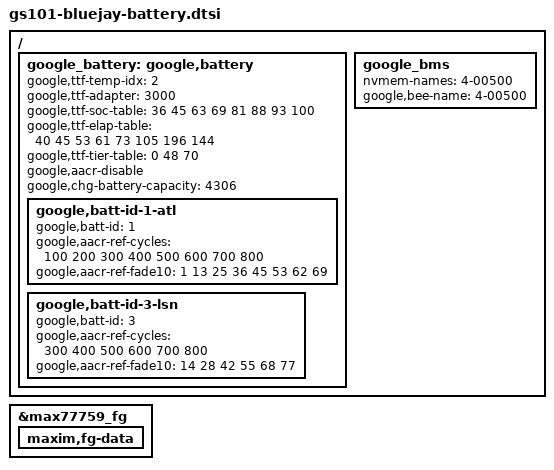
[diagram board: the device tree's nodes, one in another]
// SPDX-License-Identifier: GPL-2.0-only
/*
 * Battery device tree entries specific to bluejay
 *
 * Copyright 2021 Google,LLC
 *
 */

&google_battery {
	google,chg-battery-capacity = <4306>;
};

&max77759_fg {
	maxim,fg-data {
		#include "gs101-bluejay-battery-data.dtsi"
	};
};

/ {
	fragment@battery {
		target-path = "/";
		__overlay__ {
			google_battery: google,battery {
				google,ttf-temp-idx= <2>;
				google,ttf-adapter = <3000>;
				google,ttf-soc-table =  <36 45 63 69 81 88  93  100>;
				google,ttf-elap-table = <40 45 53 61 73 105 196 144>;
				google,ttf-tier-table = <0 48 70>;

				google,aacr-disable;

				google,batt-id-1-atl {
					google,batt-id = <1>;
					google,aacr-ref-cycles = <100 200 300 400 500 600 700 800>;
					google,aacr-ref-fade10 = <  1  13  25  36  45  53  62  69>;
				};

				google,batt-id-3-lsn {
					google,batt-id = <3>;
					google,aacr-ref-cycles = <300 400 500 600 700 800>;
					google,aacr-ref-fade10 = < 14  28  42  55  68  77>;
				};
			};
			google_bms {
				nvmem-names = "4-00500";
				/* pack eeprom is available only with P20+ batteries */
				google,bee-name = "4-00500";
			};
		};
	};
};
